# NTINY register map
Vendor: NTiny; Series: NTiny RISC-V; File version: 1.0
NTiny is a 4-stage in-order RV32IMAFC RISC-V SoC with GPIO, UART, SPI, I2C, Timer, PWM, CRC, CLINT and PLIC peripherals.
CPU: other r0p0, little endian, no MPU, FPU, 2 interrupt priority bits
Registers are 32-bit, read-write, reset 0x0 unless marked. A register's access mark holds for its fields unless they carry their own. Offsets are from the block's base; lines under a group give offsets from that group; [hi:lo] are bit positions; {n}, {i} and the like mark numbered series; 'fields as' and 'values as' point back to an identical list; <NAME> marks a mode.

## Memory map
0x02000000 CLINT size 0x10000 — Core-Local Interruptor (RISC-V SiFive layout)
0x0C000000 PLIC size 0x1000 — Platform-Level Interrupt Controller
0x10000000 UART size 0x1000 — Universal Asynchronous Receiver/Transmitter
0x10010000 SPI size 0x1000 — Serial Peripheral Interface (master)
0x10020000 I2C size 0x1000 — Inter-Integrated Circuit (master)
0x10030000 GPIO size 0x1000 — General-Purpose I/O
0x10040000 PWM size 0x1000 — Dual-channel PWM with dead-time generator
0x10050000 TIMER size 0x1000 — Programmable Timer with Compare

## Interrupts
0 UART_IRQ (UART) — UART interrupt (PLIC source 0)
1 SPI_IRQ (SPI) — SPI interrupt (PLIC source 1)
2 I2C_IRQ (I2C) — I2C interrupt (PLIC source 2)
3 GPIO_IRQ (GPIO) — GPIO interrupt (PLIC source 3)
4 PWM_IRQ (PWM) — PWM interrupt (PLIC source 4)

## GPIO — General-Purpose I/O
Base 0x10030000
0x00 DDR — Data Direction Register (1 = output)
0x04 DOUT — Data Output Register
0x08 DIN ro — Data Input Register
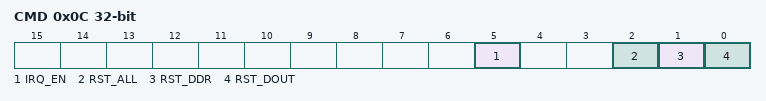
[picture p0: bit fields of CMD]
0x0C CMD wo — Command Register (reset / IRQ-enable strobes)
  [5] IRQ_EN, [2] RST_ALL, [1] RST_DDR, [0] RST_DOUT

## UART — Universal Asynchronous Receiver/Transmitter
Base 0x10000000
0x00 RX ro — Receive Data
  [7:0] DATA
0x04 TX wo — Transmit Data
  [7:0] DATA
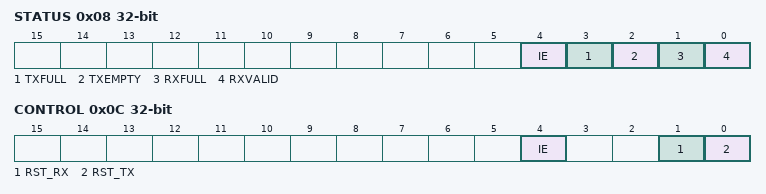
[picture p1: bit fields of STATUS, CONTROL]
0x08 STATUS ro — Status Flags
  [4] IE
  [3] TXFULL
  [2] TXEMPTY
  [1] RXFULL
  [0] RXVALID — RX FIFO has at least one byte
0x0C CONTROL
  [4] IE, [1] RST_RX, [0] RST_TX
0x10 BAUDRATE — Baud divisor: (F_CPU / baud) - 1

## SPI — Serial Peripheral Interface (master)
Base 0x10010000
0x1C DGIER — Global Interrupt Enable
  [31] GIE
0x20 IPISR — IP Interrupt Status
  [2] TX_EMPTY
0x28 IPIER — IP Interrupt Enable
  [2] TX_EMPTY
0x40 SRR wo — Soft Reset Register (write 0x0A to reset)
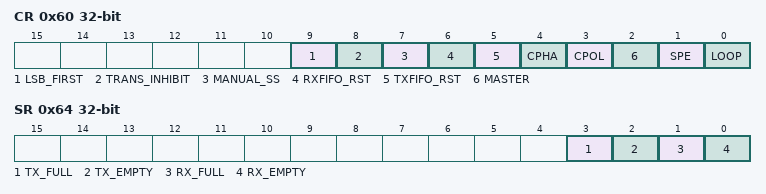
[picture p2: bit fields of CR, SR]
0x60 CR — Control Register
  [9] LSB_FIRST, [8] TRANS_INHIBIT, [7] MANUAL_SS, [6] RXFIFO_RST, [5] TXFIFO_RST, [4] CPHA, [3] CPOL, [2] MASTER, [1] SPE, [0] LOOP
0x64 SR ro — Status Register
  [3] TX_FULL, [2] TX_EMPTY, [1] RX_FULL, [0] RX_EMPTY
0x68 DTR wo — Data Transmit Register
  [7:0] DATA
0x6C DRR ro — Data Receive Register
  [7:0] DATA
0x70 SSR — Slave Select Register (active-low)
  [7:0] VALUE
0x74 CLK_RATIO — Clock Ratio Divider

## I2C — Inter-Integrated Circuit (master)
Base 0x10020000
0x00 CLK_PRESCALER — Clock divider
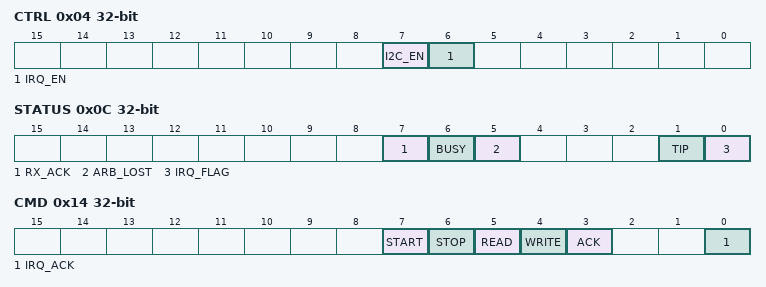
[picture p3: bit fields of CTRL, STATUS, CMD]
0x04 CTRL — Control: [7]i2c_en [6]irq_en
  [7] I2C_EN, [6] IRQ_EN
0x08 RX ro — Received byte
0x0C STATUS ro — Status flags
  [7] RX_ACK
  [6] BUSY
  [5] ARB_LOST
  [1] TIP — Transfer in progress
  [0] IRQ_FLAG
0x10 TX wo — Byte to transmit
0x14 CMD wo — Command word (start/stop/r/w/ack/irq_ack)
  [7] START, [6] STOP, [5] READ, [4] WRITE, [3] ACK, [0] IRQ_ACK

## TIMER — Programmable Timer with Compare
Base 0x10050000
0x00 CLOCK_PRESCALER — Prescaler value (clock divider - 1)
0x04 COUNT — Current counter value
0x08 CONTROL — Control [6'b0, en, 1'b0]
  [1] ENABLE
0x0C STATUS ro — Status [7'b0, count_complete]
  [0] COMPLETE
0x10 COMPARE — Compare value -- match raises STATUS.COMPLETE

## PWM — Dual-channel PWM with dead-time generator
Base 0x10040000
0x00 PRESCALER
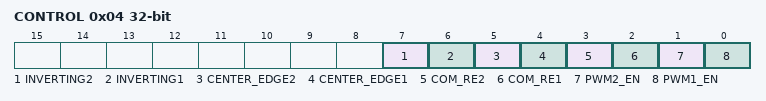
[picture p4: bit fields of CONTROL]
0x04 CONTROL
  [7] INVERTING2, [6] INVERTING1, [5] CENTER_EDGE2, [4] CENTER_EDGE1, [3] COM_RE2, [2] COM_RE1, [1] PWM2_EN, [0] PWM1_EN
0x08 PERIOD1
0x0C PERIOD2
0x10 COMPARE1
0x14 COMPARE2
0x18 DEADTIME1
0x1C DEADTIME2

## PLIC — Platform-Level Interrupt Controller
Base 0x0C000000
0x00 IE_INTERRUPT — Per-source enable mask (bit per IRQ ID)
0x04 THRESHOLD — Priority threshold (sources above threshold fire)
0x08 PRIORITY — Per-source priority encoding
0x0C INTERRUPT_ID ro — Read claims highest-priority pending IRQ

## CLINT — Core-Local Interruptor (RISC-V SiFive layout)
Base 0x02000000
0x00 MSIP — Machine-mode software interrupt pending
0x4000 MTIMECMP — Lower 32 bits of mtimecmp
0x4004 MTIMECMPH — Upper 32 bits of mtimecmp
0xBFF8 MTIME ro — Lower 32 bits of free-running mtime
0xBFFC MTIMEH ro — Upper 32 bits of free-running mtime

## Licence text in the file
Apache-2.0

## Notices in the file
SPDX-License-Identifier: Apache-2.0
